# rpi3b register map
Vendor: Raspberr Pi Foundation; Series: raspberry pi; File version: 0.1
CPU: CA53 r3p0, little endian, MPU, FPU, I-cache, D-cache, 0 interrupt priority bits
Registers are 32-bit, access not given, no defined reset value unless marked. A register's access mark holds for its fields unless they carry their own. Offsets are from the block's base; [hi:lo] are bit positions.

## Auxillaries — The Device has three Auxiliary peripherals: One mini UART and two SPI masters. These three peripheral are grouped together as they share the same area in the peripheral register map and they share a common interrupt. Also all three are controlled by the auxiliary enable register.
Base ?
0x00 IRQ 3-bit ro — The AUXIRQ register is used to check any pending interrupts which may be asserted by the three Auxiliary sub blocks.
  [2] Spi2IRQ — If set the SPI 2 module has an interrupt pending.
  [1] Spi1IRQ — If set the SPI 1 module has an interrupt pending.
  [0] MiniUARTIRQ — If set the Mini UART module has an interrupt pending.
0x04 Enable 3-bit rw — The AUXENB register is used to enable the three modules; UART, SPI1, SPI2.
  [2] Spi2Enable — If set the SPI 2 module is enabled. If clear the SPI 2 module is disabled. That also disables any SPI 2 module register access
  [1] Spi1Enable — If set the SPI 1 module is enabled. If clear the SPI 1 module is disabled. That also disables any SPI 1 module register access
  [0] MiniUARTEnable — If set the mini UART is enabled. The UART will immediately start receiving data, especially if the UART1_RX line is low. If clear the mini UART is disabled. That also disables any mini UART register access
0x40 MiniUARTData 8-bit access per field — The AUX_MU_IO_REG register is primary used to write data to and read data from the UART FIFOs. If the DLAB bit in the line control register is set this register gives access to the LS 8 bits of the baud rate. (Note: there is easier access to the baud rate register)
  [7:0] Tx wo — Data written is put in the transmit FIFO (Provided it is not full)
  [7:0] Rx ro — Data written is put in the transmit FIFO (Provided it is not full)
0x44 MiniUARTInterruptEnable 2-bit rw — The AUX_MU_IER_REG register is primary used to enable interrupts
  [3:0] Interrupts — Enable or Disable Interrupts For Receive and Transmit
    0=None (Turn off Receive and Transmit interrupts); 5=Receive (Send interrupt when at least one symbol is available in receive FIFO); 10=Transmit (Send interrupt when the transmit FIFO is empty)
0x48 MiniUARTInterruptStatus 8-bit access per field — The AUX_MU_IIR_REG register shows the interrupt status. It also has two FIFO enable status bits and (when writing) FIFO clear bits.
  [7:6] FIFOEnables ro — Both bits always read as 1 as the FIFOs are always enabled
  [2:1] InterruptID ro — On read this register shows the interrupt ID bit
    0=NoInterrupts; 1=TransmitEmpty (Transmit holding register empty); 2=ReceiverReady (Receiver holds valid byte)
  [2:1] FIFOClear wo — On write, writing with bit 1 set will clear the receive FIFO Writing with bit 2 set will clear the transmit FIFO
    1=Transmit; 2=Receive; 3=TransmitAndReceive
  [0] InterruptPending ro — This bit is clear whenever an interrupt is pending
0x4C MiniUARTLineControl 7-bit rw — The AUX_MU_LCR_REG register controls the line data format.
  [6] Break — If set high the UART1_TX line is pulled low continuously. If held for at least 12 bits times that will indicate a break condition.
  [1:0] DataSize — If clear the UART works in 7-bit mode If set the UART works in 8-bit mode. The documentation in the data sheet is actually wrong on this one, so I used the known to work values.
    0=SevenBit; 3=EightBit
0x50 MiniUARTModemControl 2-bit rw — The AUX_MU_MCR_REG register controls the 'modem' signals.
  [1] RTS — If clear the UART1_RTS line is high If set the UART1_RTS line is low. This bit is ignored if the RTS is used for auto-flow control (See the Mini Uart Extra Control register description).
0x54 MiniUARTLineStatus 7-bit ro — The AUX_MU_LSR_REG register shows the data status.
  [6] TransmitterIdle — This bit is set if the transmit FIFO is empty and the transmitter is idle. (Finished shifting out the last bit).
  [5] TransmitterEmpty — This bit is set if the transmit FIFO can accept at least one byte.
  [1] ReceiverOverrun read-clears — This bit is set if there was a receiver overrun. That is: one or more characters arrived whilst the receive FIFO was full. The newly arrived charters have been discarded. This bit is cleared each time this register is read. To do a non-destructive read of this overrun bit use the Mini Uart Extra Status register.
  [0] DataReady — This bit is set if the receive FIFO holds at least 1 symbol.
0x58 MiniUARTModemStatus 6-bit ro — The AUX_MU_MSR_REG register shows the 'modem' status.
  [5] CTS — This bit is the inverse of the UART1_CTS input Thus : If set the UART1_CTS pin is low If clear the UART1_CTS pin is high
0x5C MiniUARTScratch 8-bit rw — AUX_MU_SCRATCH is a single byte storage.
  [7:0] Scratch — One whole byte extra on top of the 134217728 provided by the SDC
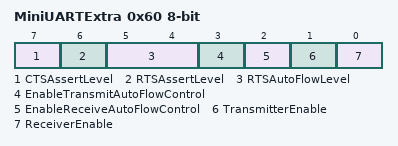
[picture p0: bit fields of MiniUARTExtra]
0x60 MiniUARTExtra 8-bit rw — The AUX_MU_CNTL_REG provides access to some extra useful and nice features not found on a normal 16550 UART .
  [7] CTSAssertLevel — This bit allows one to invert the CTS auto flow operation polarity. If set the CTS auto flow assert level is low* If clear the CTS auto flow assert level is high*
  [6] RTSAssertLevel — This bit allows one to invert the RTS auto flow operation polarity. If set the RTS auto flow assert level is low* If clear the RTS auto flow assert level is high*
  [5:4] RTSAutoFlowLevel — These two bits specify at what receiver FIFO level the RTS line is de-asserted in auto-flow mode.
    0=DeassertRTSWith3Empty; 1=DeassertRTSWith2Empty; 2=DeassertRTSWith1Empty; 3=DeassertRTSWith4Empty
  [3] EnableTransmitAutoFlowControl — If this bit is set the transmitter will stop if the CTS line is de-asserted. If this bit is clear the transmitter will ignore the status of the CTS line
  [2] EnableReceiveAutoFlowControl — If this bit is set the RTS line will de-assert if the receive FIFO reaches it 'auto flow' level. In fact the RTS line will behave as an RTR (Ready To Receive) line. If this bit is clear the RTS line is controlled by the AUX_MU_MCR_REG register bit 1.
  [1] TransmitterEnable — If this bit is set the mini UART transmitter is enabled. If this bit is clear the mini UART transmitter is disabled
  [0] ReceiverEnable — If this bit is set the mini UART receiver is enabled. If this bit is clear the mini UART receiver is disabled
0x64 MiniUARTStatus 28-bit ro — The AUX_MU_STAT_REG provides a lot of useful information about the internal status of the mini UART not found on a normal 16550 UART.
  [27:24] TransmitFIFOFillLevel — These bits shows how many symbols are stored in the transmit FIFO. The value is in the range 0-8.
  [19:16] ReceiveFIFOFillLevel — These bits shows how many symbols are stored in the receive FIFO. The value is in the range 0-8.
  [9] TransmitterDone — This bit is set if the transmitter is idle and the transmit FIFO is empty.
  [8] TransmitFIFOEmpty — If this bit is set the transmitter FIFO is empty. Thus it can accept 8 symbols
  [7] CTSStatus — This bit shows the status of the UART1_CTS line.
  [6] RTSStatus — This bit shows the status of the UART1_RTS line.
  [5] TransmitFIFOFull — If this bit is set the transmitter FIFO is full.
  [4] ReceiverOverrun — This bit is set if there was a receiver overrun. That is: one or more characters arrived whilst the receive FIFO was full. The newly arrived characters have been discarded. This bit is cleared each time the AUX_MU_LSR_REG register is read.
  [3] TransmitterIdle — If this bit is set the transmitter is idle. If this bit is clear the transmitter is idle [??busy??].
  [2] ReceiverIdle — If this bit is set the receiver is idle. If this bit is clear the receiver is busy. This bit can change unless the receiver is disabled.
  [1] SpaceAvailable — If this bit is set the mini UART transmitter FIFO can accept at least one more symbol. If this bit is clear the mini UART transmitter FIFO is full.
  [0] SymbolAvailable — If this bit is set the mini UART receive FIFO contains at least 1 symbol If this bit is clear the mini UART receiver FIFO is empty
0x68 MiniUARTBaud 16-bit rw — The AUX_MU_BAUD register allows direct access to the 16-bit wide baudrate counter.
  [15:0] BaudrateCounter
